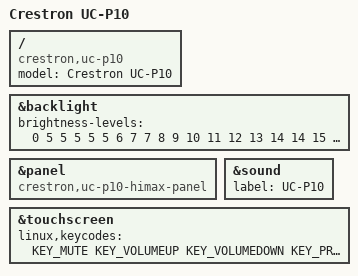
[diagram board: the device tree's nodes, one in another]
// SPDX-License-Identifier: (GPL-2.0+ OR MIT)
/*
 * Crestron UC-P10 room phone: 1200x1920 MIPI-DSI panel with a Himax
 * HX8279-family controller.
 */

/dts-v1/;

#include "rk3399-crestron-uc-pxx.dtsi"

/ {
	model = "Crestron UC-P10";
	compatible = "crestron,uc-p10", "rockchip,rk3399";
};

&backlight {
	/*
	 * The stock "brightness-levels-p10" table. The highest duty cycle
	 * is 225/255.
	 */
	brightness-levels = <
		  0   5   5   5   5   5   6   7
		  7   8   9  10  11  12  13  14
		 14  15  16  17  18  19  20  21
		 21  22  23  24  25  26  27  28
		 28  29  30  31  32  33  34  35
		 35  36  37  38  39  40  41  42
		 42  43  44  45  46  47  48  49
		 49  50  51  52  53  54  55  56
		 56  57  58  59  60  61  62  63
		 63  64  65  66  67  68  69  70
		 70  71  72  73  74  75  76  77
		 77  78  79  80  81  82  83  84
		 84  85  86  87  88  89  90  91
		 91  92  93  94  95  96  97  98
		 98  99 100 101 102 103 104 105
		105 106 107 108 109 110 111 112
		112 113 114 115 116 117 118 119
		119 120 121 122 123 124 125 126
		126 127 128 129 130 131 132 133
		133 134 135 136 137 138 139 140
		140 141 142 143 144 145 146 147
		147 148 149 150 151 152 153 154
		154 155 156 157 158 159 160 161
		161 162 163 164 165 166 167 168
		168 169 170 171 172 173 174 175
		175 176 177 178 179 180 181 182
		182 183 184 185 186 187 188 189
		189 190 191 192 193 194 195 196
		196 197 198 199 200 201 202 203
		203 204 205 206 207 208 209 210
		210 211 212 213 214 215 216 217
		218 219 220 221 222 223 224 225>;
};

&panel {
	compatible = "crestron,uc-p10-himax-panel";
};

&sound {
	label = "UC-P10";
};

&touchscreen {
	/*
	 * T15 key array: CTRL 0x03, 6x1 at X35/Y22. T19 (GPIO) and T97 are
	 * disabled in the chip configuration. The key order is the stock
	 * "linux,gpio-keymap_p10". The coordinates (X 0..1919, Y 0..1199)
	 * already match the upright landscape UI. The chip T100 object has
	 * INVERTX and INVERTY set, and stock Android uses the values as they
	 * are with ro.sf.hwrotation=270. So no swap or invert is necessary.
	 */
	linux,keycodes = <KEY_MUTE KEY_VOLUMEUP KEY_VOLUMEDOWN
			  KEY_PROG3 KEY_PROG2 KEY_PROG1>;
};
